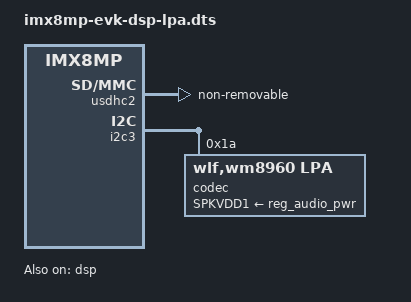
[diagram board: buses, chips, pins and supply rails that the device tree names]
// SPDX-License-Identifier: (GPL-2.0+ OR MIT)
/*
 * Copyright 2020 NXP
 */

/dts-v1/;

#include "imx8mp-evk-dsp.dts"

&usdhc2 {
	non-removable;
};

&i2c3 {
	codec: wm8960@1a {
		compatible = "wlf,wm8960,lpa";
		reg = <0x1a>;
		clocks = <&audiomix_clk IMX8MP_CLK_AUDIOMIX_SAI3_MCLK1>;
		clock-names = "mclk";
		wlf,shared-lrclk;
		SPKVDD1-supply = <&reg_audio_pwr>;
	};
};

/ {
	sound-dsp {
		compatible = "fsl,imx-dsp-audio-lpa";
		model = "wm8960-audio";
		cpu-dai = <&dspaudio>;
		audio-codec = <&codec>;
		audio-platform = <&dsp>;
	};
};

&dsp {
	compatible = "fsl,imx8mp-dsp-lpa";
	ocram = <&ocram>;
	fsl,dsp-firmware = "imx/dsp/hifi4_imx8mp_lpa.bin";
	status = "okay";
};
